# ESP32S31_RADIO register map
Vendor: Espressif; Series: ESP32-S31; File version: 3.52
Registers are 32-bit, read-write, no defined reset value unless marked. A register's access mark holds for its fields unless they carry their own. Offsets are from the block's base; [hi:lo] are bit positions; lines under a group give offsets from that group; {n}, {i} and the like mark numbered series.

## WIFI_MAC_HE_OBSS_NARROW_BAND_RU — Complete hal_he_disable_obss_narrow_bw_ru writes either all ones or zero into the twenty-bit bitmap and independently sets or clears a five-bit class group and the global disable bit. The leaf name proves the aggregate disable function; individual bitmap/class identities remain approximate.
Base 0x20104E9C
0x00 DISABLE_BITMAP — Project-assigned name. Twenty-bit OBSS narrow-band RU disable bitmap written as 0xfffff when disabled and zero when enabled.
  [19:0] VALUE — Project-assigned name.
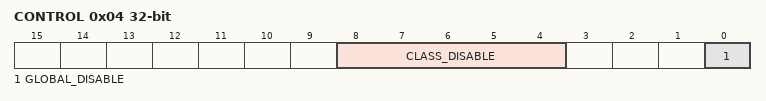
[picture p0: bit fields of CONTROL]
0x04 CONTROL — Project-assigned name. The complete leaf updates CLASS_DISABLE bits first and GLOBAL_DISABLE second through independent fresh-read RMWs.
  [8:4] CLASS_DISABLE — Project-assigned name. Approximate functional name for the five bits toggled together by hal_he_disable_obss_narrow_bw_ru.
  [0] GLOBAL_DISABLE — Project-assigned name.

## WIFI_MAC_TX_POWER_INIT — Complete hal_init_tx_pwr consumes 43 two-byte PHY power results, then complete TB, immediate-response and TB-RU leaves publish 56 ordered fresh-read RMW edges. Runtime partial-RU get/set APIs select the same packed fields by the raw Trigger RU allocation. Values are PHY gain-table indices, not dBm.
Base 0x20104408
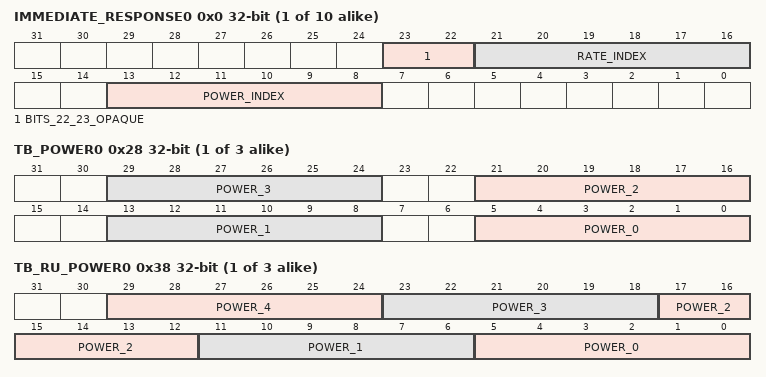
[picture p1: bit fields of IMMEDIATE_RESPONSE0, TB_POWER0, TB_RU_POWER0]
{0x0+4i} IMMEDIATE_RESPONSE{i} (i=0..9) — Project-assigned name. Ten immediate-response command words. Complete hal_init_imrsp_power separately replaces format, rate and power-index fields in that order.
  [23:22] BITS_22_23_OPAQUE — Opaque: meaning not established. Zero for the six legacy response words and two for the four HE response words.
  [21:16] RATE_INDEX — Project-assigned name.
  [13:8] POWER_INDEX — Project-assigned name. PHY gain-table index selected for the response rate; not dBm.
{0x28+4i} TB_POWER{i} (i=0..2) — Project-assigned name. Three trigger-based power words populated from rates 16 through 25. Each used six-bit field is updated through a separate RMW.
  [8n+5:8n] POWER_{n} (n=0..3) — Project-assigned name.
0x34 TB_RU_POWER_TAIL — Project-assigned name. Complete hal_init_tb_ru_power publishes the unadjusted rate-16 power at raw Trigger RU selector 61. Complete runtime get/set leaves address this same six-bit field; selector 62 is rejected.
  [29:24] POWER_INDEX — Project-assigned name.
{0x38+4i} TB_RU_POWER{i} (i=0..2) — Project-assigned name. Packed trigger-based resource-unit power deltas selected by raw Trigger RU allocation. Complete runtime get/set jump tables admit only selectors 0 through 8, 37 through 40, 53, 54 and 61; the first fifteen selectors occupy these packed words and selector 61 occupies TB_RU_POWER_TAIL.
  [6n+5:6n] POWER_{n} (n=0..4) — Project-assigned name.

## WIFI_MAC_COEX_INIT — Complete COEX/PTI tail of hal_init and complete setter leaves. PTI values remain platform-supplied because the coexistence table may be changed at runtime.
Base 0x201042FC
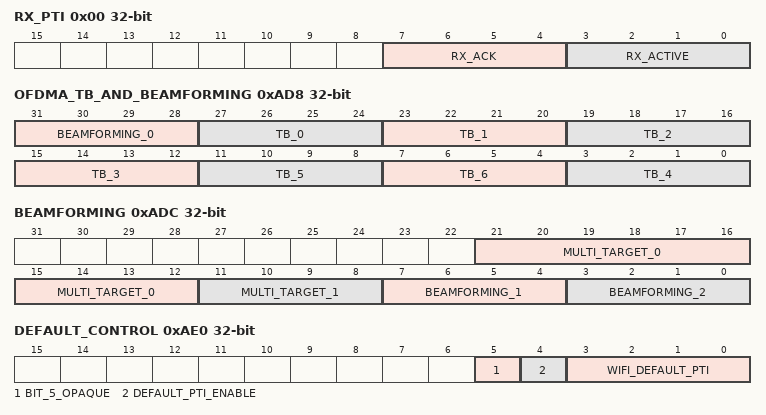
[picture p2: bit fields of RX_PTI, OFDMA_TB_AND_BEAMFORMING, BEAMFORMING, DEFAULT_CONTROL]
0x00 RX_PTI — Project-assigned name. Complete hal_init replaces RX-active and RX-ACK nibbles through two separate setter RMWs.
  [7:4] RX_ACK — Project-assigned name. PTI returned for event three and published by hal_set_rx_ack_pti.
  [3:0] RX_ACTIVE — Project-assigned name. Complete hal_init passes zero to hal_set_rx_active_pti.
0xAD8 OFDMA_TB_AND_BEAMFORMING — Project-assigned name. Seven trigger-based PTIs and one beamforming PTI, each published through a separate fresh-read RMW by complete setters.
  [31:28] BEAMFORMING_0 — Project-assigned name.
  [27-4n:24-4n] TB_{n} (n=0..3) — Project-assigned name.
  [11:8] TB_5 — Project-assigned name.
  [7:4] TB_6 — Project-assigned name.
  [3:0] TB_4 — Project-assigned name.
0xADC BEAMFORMING — Project-assigned name. Two ordinary and two multi-target beamforming PTI fields, programmed through four separate fresh-read RMWs.
  [21:12] MULTI_TARGET_0 — Project-assigned name. Complete hal_set_beamf_mt_pti replaces bits 21:12 with its unmasked first argument; cold PTI values occupy only the low nibble of this ten-bit field.
  [11:8] MULTI_TARGET_1 — Project-assigned name.
  [7:4] BEAMFORMING_1 — Project-assigned name.
  [3:0] BEAMFORMING_2 — Project-assigned name.
0xAE0 DEFAULT_CONTROL — Project-assigned name. Common COEX enable/default PTI word updated by three separate setter RMWs.
  [5] BIT_5_OPAQUE — Opaque: meaning not established. Set by complete hal_coex_pti_init.
  [4] DEFAULT_PTI_ENABLE — Project-assigned name. Set by hal_coex_enable_default_pti(1).
  [3:0] WIFI_DEFAULT_PTI — Project-assigned name. PTI returned for event fifteen.
